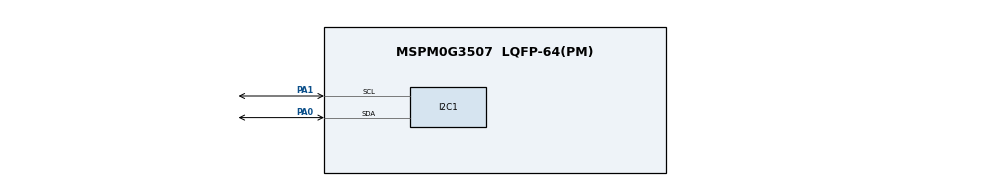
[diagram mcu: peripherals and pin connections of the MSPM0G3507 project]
// @cliArgs --device "MSPM0G350X" --package "LQFP-64(PM)" --part "Default" 
// @v2CliArgs --device "MSPM0G3507" --package "LQFP-64(PM)" 
// @cliArgs --board /ti/boards/LP_MSPM0G3507 --rtos nortos

/**
 * Import the modules used in this configuration.
 */
const Board = scripting.addModule("/ti/driverlib/Board");
const CRC   = scripting.addModule("/ti/driverlib/CRC");
const DMA   = scripting.addModule("/ti/driverlib/DMA");
const I2C   = scripting.addModule("/ti/driverlib/I2C", {}, false);
const I2C1  = I2C.addInstance();

/**
 * Write custom configuration values to the imported modules.
 */

CRC.polynomial = "16_POLYNOMIAL";
CRC.seed       = 0xFFFF;

I2C1.$name                            = "I2C_0";
I2C1.basicEnableTarget                = true;
I2C1.basicTargetAddress               = 0x48;
I2C1.DMAEvent2                        = "TARGET_RXFIFO_TRIGGER";
I2C1.DMAEvent1                        = "TARGET_TXFIFO_TRIGGER";
I2C1.advTargetTXEmptyEn               = true;
I2C1.intTarget                        = ["START","STOP","TXFIFO_EMPTY"];
I2C1.peripheral.$assign               = "I2C0";
I2C1.peripheral.sdaPin.$assign        = "PA0";
I2C1.peripheral.sclPin.$assign        = "PA1";
I2C1.DMA_CHANNEL_EVENT2.addressMode   = "f2b";
I2C1.DMA_CHANNEL_EVENT2.dstLength     = "BYTE";
I2C1.DMA_CHANNEL_EVENT2.destIncrement = "INCREMENT";
I2C1.DMA_CHANNEL_EVENT2.$name         = "DMA_CH_RX";
I2C1.DMA_CHANNEL_EVENT1.srcLength     = "BYTE";
I2C1.DMA_CHANNEL_EVENT1.addressMode   = "b2f";
I2C1.DMA_CHANNEL_EVENT1.srcIncrement  = "INCREMENT";
I2C1.DMA_CHANNEL_EVENT1.$name         = "DMA_CH_TX";

const SYSCTL = scripting.addModule("/ti/driverlib/SYSCTL", {}, false);
